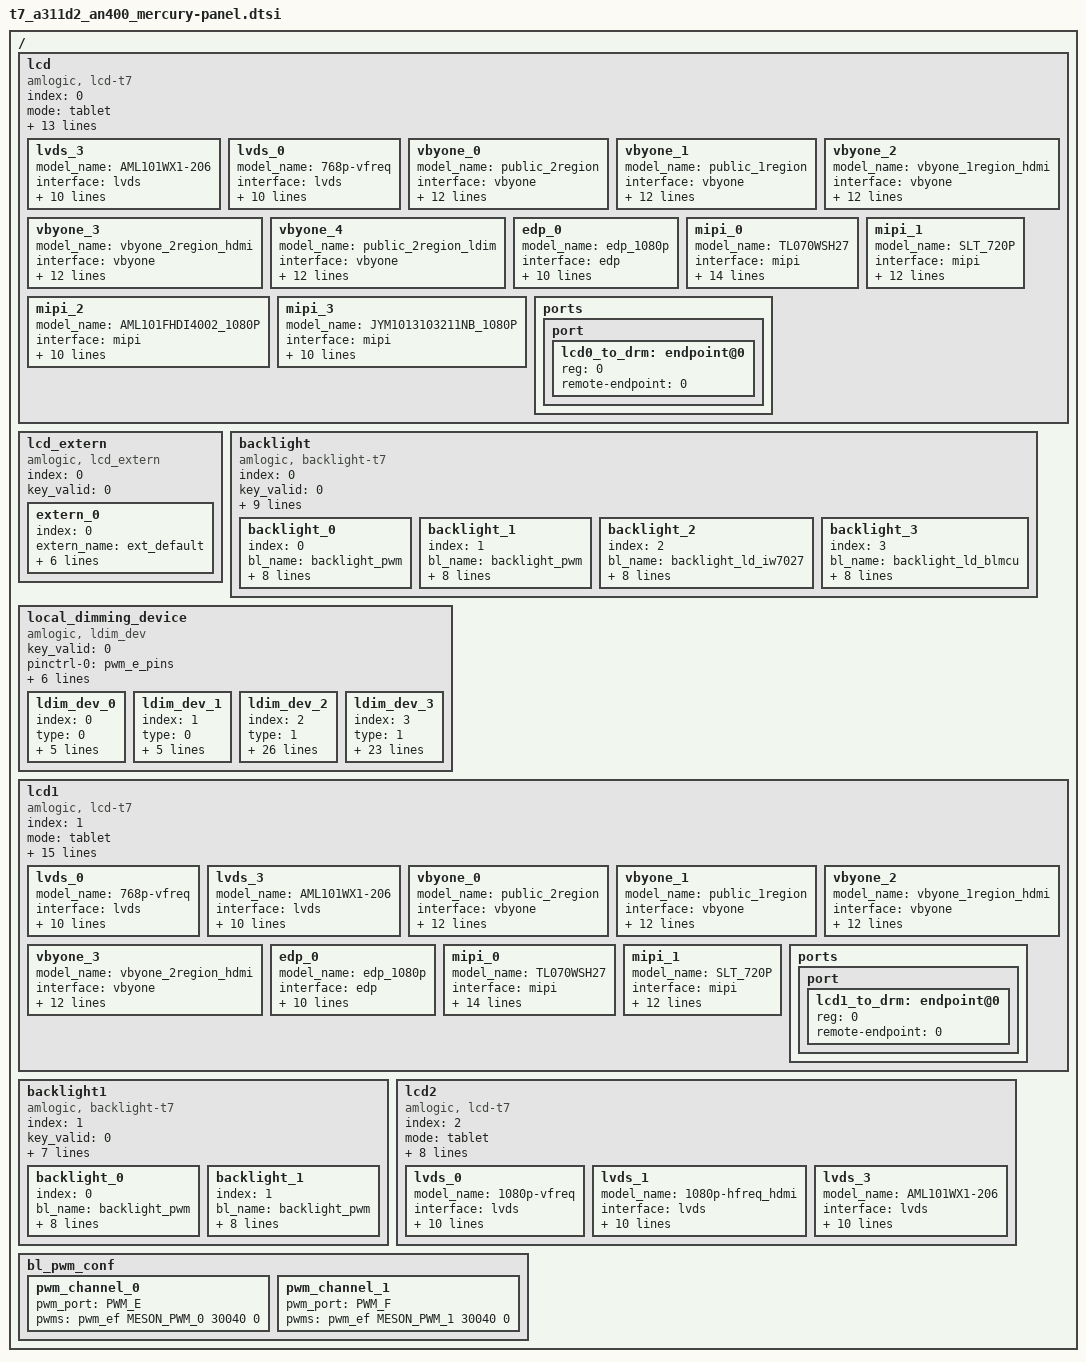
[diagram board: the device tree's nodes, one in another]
// SPDX-License-Identifier: (GPL-2.0+ OR MIT)
/*
 * Copyright (c) 2019 Amlogic, Inc. All rights reserved.
 */

/ {
	lcd:lcd {
		compatible = "amlogic, lcd-t7";
		status = "okay";
		index = <0>;
		mode = "tablet";
		fr_auto_policy = <0>; /* 0=disable, 1=60/50hz, 2=60/50/48hz */
		key_valid = <0>;
		clocks = <&clkc CLKID_MIPI_DSI_A
			&clkc CLKID_DSI0_PHY_GATE
			&clkc CLKID_DSI_A_MEAS_GATE>;
		clock-names = "dsi_host_gate",
			"dsi_phy_gate",
			"dsi_meas";
		reg = <0x0 0xfe018000 0x0 0x60	   /* combo dphy */
			0x0 0xfe0b0000 0x0 0x10b0  /* edp_a host */
			0x0 0xfe074000 0x0 0x400   /* mipi_dsi_a host */
			0x0 0xfe014000 0x0 0x200   /* mipi_dsi_a phy */
			0x0 0xfe002000 0x0 0xa0	   /* reset */
			0x0 0xfe004000 0x0 0x70>;  /* periphs */
		interrupts = <0 197 1
			0 194 1
			0 82 1
			0 282 1>;
		interrupt-names = "vsync","vsync2","vsync3","vbyone";
		pinctrl-names = "vbyone","vbyone_off","edp","edp_off";
		pinctrl-0 = <&lcd_vbyone_a_pins>;
		pinctrl-1 = <&lcd_vbyone_a_off_pins>;
		pinctrl-2 = <&lcd_edp_a_pins>;
		pinctrl-3 = <&lcd_edp_a_off_pins>;
		pinctrl_version = <2>; /* for uboot */

		/* power type:(0=cpu_gpio, 2=signal, 3=extern, 0xff=ending) */
		/* power index:(gpios_index, or extern_index, 0xff=invalid) */
		/* power value:(0=output low, 1=output high, 2=input) */
		/* power delay:(unit in ms) */
		/*lcd_cpu-gpios = <&gpio GPIOY_0 GPIO_ACTIVE_HIGH */
		/*	&gpio GPIOY_4 GPIO_ACTIVE_HIGH */
		/*	&gpio GPIOY_6 GPIO_ACTIVE_HIGH>; */
		/*lcd_cpu_gpio_names = "GPIOY_0","GPIOY_4","GPIOY_6";*/

		lvds_3{
			model_name = "AML101WX1-206";
			interface = "lvds"; /*lcd_interface(lvds, vbyone)*/
			basic_setting = <
				1280 800 /*h_active, v_active*/
				1310 813 /*h_period, v_period*/
				8	   /*lcd_bits*/
				217 136>; /*screen_widht, screen_height*/
			range_setting = <
				1280 1280 /*h_period_min, max */
				800 800	 /*v_period_min, max */
				400000000 800000000>; /*pclk_min, max*/
			lcd_timing = <
				2 14 0	 /*hs_width, hs_bp, hs_pol*/
				1 6 0>; /*vs_width, vs_bp, vs_pol*/
			clk_attr = <
				0 /*fr_adj_type
				   *(0=clk, 1=htotal, 2=vtotal, 3=auto_range,
				   * 4=hdmi_mode)
				   */
				15 /*clk_ss_level*/
				1 /*clk_auto_generate*/
				60>; /*pixel_clk(unit in Hz)*/
			lvds_attr = <
				1  /*lvds_repack*/
				0  /*dual_port*/
				0  /*pn_swap*/
				1  /*port_swap*/
				0>; /*lane_reverse*/
			phy_attr=<0x3 0>; /*vswing_level, preem_level*/

			/* power step: type, index, value, delay(ms) */
			power_on_step = <
				0 0 1 50  /*panel power on*/
				2 0 0 0	  /*signal enable*/
				0xff 0 0 0>; /*ending*/
			power_off_step = <
				2 0 0 10  /*signal disable*/
				0 0 0 100  /*panel power off*/
				0xff 0 0 0>; /*ending*/
			backlight_index = <0xff>;
		};
		lvds_0{
			model_name = "768p-vfreq";
			interface = "lvds"; /*lcd_interface(lvds, vbyone)*/
			basic_setting = <
				1366 768 /*h_active, v_active*/
				1560 806 /*h_period, v_period*/
				8	   /*lcd_bits*/
				16 9>; /*screen_widht, screen_height*/
			range_setting = <
				1460 2000 /*h_period_min, max */
				784 1015  /*v_period_min, max */
				50000000 85000000>; /*pclk_min, max*/
			lcd_timing = <
				56 64 0	  /*hs_width, hs_bp, hs_pol*/
				3  28 0>; /*vs_width, vs_bp, vs_pol*/
			clk_attr = <
				2 /*fr_adj_type
				   *(0=clk, 1=htotal, 2=vtotal, 3=auto_range,
				   * 4=hdmi_mode)
				   */
				15 /*clk_ss_level*/
				1 /*clk_auto_generate*/
				0>; /*pixel_clk(unit in Hz)*/
			lvds_attr = <
				1  /*lvds_repack*/
				0  /*dual_port*/
				0  /*pn_swap*/
				0  /*port_swap*/
				0>; /*lane_reverse*/
			phy_attr=<0x3 0>; /*vswing_level, preem_level*/

			/* power step: type, index, value, delay(ms) */
			power_on_step = <
				0 0 1 50  /*panel power on*/
				2 0 0 0	  /*signal enable*/
				0xff 0 0 0>; /*ending*/
			power_off_step = <
				2 0 0 10  /*signal disable*/
				0 0 0 100 /*panel power off*/
				0xff 0 0 0>; /*ending*/
			backlight_index = <0xff>;
		};
		vbyone_0{
			model_name = "public_2region";
			interface = "vbyone"; /*lcd_interface(lvds, vbyone)*/
			basic_setting = <
				3840 2160 /*h_active, v_active*/
				4400 2250 /*h_period, v_period*/
				10	   /*lcd_bits */
				16 9>; /*screen_widht, screen_height*/
			range_setting = <
				4240 4800 /*h_period_min, max*/
				2200 2760 /*v_period_min, max*/
				480000000 624000000>; /*pclk_min, max*/
			lcd_timing = <
				33 477 0  /*hs_width, hs_bp, hs_pol*/
				6  65 0>; /*vs_width, vs_bp, vs_pol*/
			clk_attr = <
				2 /*fr_adj_type
				   *(0=clk, 1=htotal, 2=vtotal, 3=auto_range,
				   * 4=hdmi_mode)
				   */
				0 /*clk_ss_level*/
				1 /*clk_auto_generate*/
				0>; /*pixel_clk(unit in Hz)*/
			vbyone_attr = <
				8 /*lane_count*/
				2 /*region_num*/
				4 /*byte_mode*/
				4>; /*color_fmt*/
			vbyone_intr_enable = <
				1 /*vbyone_intr_enable */
				3>; /*vbyone_vsync_intr_enable*/
			phy_attr=<0x7 1>; /* vswing_level, preem_level */
			hw_filter=<0 0>;  /* filter_time, filter_cnt*/

			/* power step: type, index, value, delay(ms) */
			power_on_step = <
				0 0 1 200  /*panel power on*/
				2 0 0 10  /*signal enable*/
				0xff 0 0 0>; /*ending*/
			power_off_step = <
				2 0 0 10 /*signal disable*/
				0 0 0 500 /*panel power off*/
				0xff 0 0 0>; /*ending*/
			backlight_index = <0>;
		};
		vbyone_1{
			model_name = "public_1region";
			interface = "vbyone"; /*lcd_interface(lvds, vbyone)*/
			basic_setting = <
				3840 2160 /*h_active, v_active*/
				4400 2250 /*h_period, v_period*/
				10	   /*lcd_bits*/
				16 9>; /*screen_widht, screen_height*/
			range_setting = <
				4240 4800 /*h_period_min, max*/
				2200 2790 /*v_period_min, max*/
				552000000 632000000>; /*pclk_min,max*/
			lcd_timing = <
				33 477 0   /*hs_width, hs_bp, hs_pol*/
				6  65  0>; /*vs_width, vs_bp, vs_pol*/
			clk_attr = <
				2 /*fr_adj_type
				   *(0=clk, 1=htotal, 2=vtotal, 3=auto_range,
				   * 4=hdmi_mode)
				   */
				0 /*clk_ss_level*/
				1 /*clk_auto_generate*/
				0>; /*pixel_clk(unit in Hz)*/
			vbyone_attr = <
				8 /*lane_count*/
				1 /*region_num*/
				4 /*byte_mode*/
				4>; /*color_fmt*/
			vbyone_intr_enable = <
				1	/*vbyone_intr_enable*/
				3>; /*vbyone_vsync_intr_enable*/
			phy_attr=<0x7 1>; /* vswing_level, preem_level */
			hw_filter=<0 0>;  /* filter_time, filter_cnt*/

			/* power step: type, index, value, delay(ms) */
			power_on_step = <
				0 0 1 200  /*panel power on*/
				2 0 0 10 /*signal enable*/
				0xff 0 0 0>; /*ending*/
			power_off_step = <
				2 0 0 10  /*signal disable*/
				0 0 0 500 /*panel power off*/
				0xff 0 0 0>; /*ending*/
			backlight_index = <0>;
		};
		vbyone_2{
			model_name = "vbyone_1region_hdmi";
			interface = "vbyone"; /*lcd_interface(lvds, vbyone)*/
			basic_setting = <
				3840 2160 /*h_active, v_active*/
				4400 2250 /*h_period, v_period*/
				10	   /*lcd_bits */
				16 9>; /*screen_widht, screen_height*/
			range_setting = <
				4240 4800 /*h_period_min, max*/
				2200 2760 /*v_period_min, max*/
				480000000 624000000>; /*pclk_min, max*/
			lcd_timing = <
				33 477 0  /*hs_width, hs_bp, hs_pol*/
				6  65 0>; /*vs_width, vs_bp, vs_pol*/
			clk_attr = <
				4 /*fr_adj_type
				   *(0=clk, 1=htotal, 2=vtotal, 3=auto_range,
				   * 4=hdmi_mode)
				   */
				0 /*clk_ss_level*/
				1 /*clk_auto_generate*/
				0>; /*pixel_clk(unit in Hz)*/
			vbyone_attr = <
				8 /*lane_count*/
				1 /*region_num*/
				4 /*byte_mode*/
				4>; /*color_fmt*/
			vbyone_intr_enable = <
				1 /*vbyone_intr_enable */
				3>; /*vbyone_vsync_intr_enable*/
			phy_attr=<0x7 1>; /* vswing_level, preem_level */
			hw_filter=<0 0>;  /* filter_time, filter_cnt*/

			/* power step: type, index, value, delay(ms) */
			power_on_step = <
				0 0 1 20  /*panel power on*/
				2 0 0 0	 /*signal enable*/
				0xff 0 0 0>; /*ending*/
			power_off_step = <
				2 0 0 20 /*signal disable*/
				0 0 0 100 /*panel power off*/
				0xff 0 0 0>; /*ending*/
			backlight_index = <0xff>;
		};
		vbyone_3{
			model_name = "vbyone_2region_hdmi";
			interface = "vbyone"; /*lcd_interface(lvds, vbyone)*/
			basic_setting = <
				3840 2160 /*h_active, v_active*/
				4400 2250 /*h_period, v_period*/
				10	   /*lcd_bits */
				16 9>; /*screen_widht, screen_height*/
			range_setting = <
				4240 4800 /*h_period_min, max*/
				2200 2760 /*v_period_min, max*/
				480000000 624000000>; /*pclk_min, max*/
			lcd_timing = <
				33 477 0  /*hs_width, hs_bp, hs_pol*/
				6  65 0>; /*vs_width, vs_bp, vs_pol*/
			clk_attr = <
				4 /*fr_adj_type
				   *(0=clk, 1=htotal, 2=vtotal, 3=auto_range,
				   * 4=hdmi_mode)
				   */
				0 /*clk_ss_level*/
				1 /*clk_auto_generate*/
				0>; /*pixel_clk(unit in Hz)*/
			vbyone_attr = <
				8 /*lane_count*/
				2 /*region_num*/
				4 /*byte_mode*/
				4>; /*color_fmt*/
			vbyone_intr_enable = <
				1 /*vbyone_intr_enable */
				3>; /*vbyone_vsync_intr_enable*/
			phy_attr=<0x7 1>; /* vswing_level, preem_level */
			hw_filter=<0 0>;  /* filter_time, filter_cnt*/

			/* power step: type, index, value, delay(ms) */
			power_on_step = <
				0 0 1 20  /*panel power on*/
				2 0 0 0	 /*signal enable*/
				0xff 0 0 0>; /*ending*/
			power_off_step = <
				2 0 0 20 /*signal disable*/
				0 0 0 100 /*panel power off*/
				0xff 0 0 0>; /*ending*/
			backlight_index = <0xff>;
		};
		vbyone_4{/*for localdimming*/
			model_name = "public_2region_ldim";
			interface = "vbyone"; /*lcd_interface(lvds, vbyone)*/
			basic_setting = <
				3840 2160 /*h_active, v_active*/
				4400 2250 /*h_period, v_period*/
				10	   /*lcd_bits */
				16 9>; /*screen_widht, screen_height*/
			range_setting = <
				4240 4800 /*h_period_min, max*/
				2200 2760 /*v_period_min, max*/
				480000000 624000000>; /*pclk_min, max*/
			lcd_timing = <
				33 477 0  /*hs_width, hs_bp, hs_pol*/
				6  65 0>; /*vs_width, vs_bp, vs_pol*/
			clk_attr = <
				2 /*fr_adj_type
				   *(0=clk, 1=htotal, 2=vtotal, 3=auto_range,
				   * 4=hdmi_mode)
				   */
				0 /*clk_ss_level*/
				1 /*clk_auto_generate*/
				0>; /*pixel_clk(unit in Hz)*/
			vbyone_attr = <
				8 /*lane_count*/
				2 /*region_num*/
				4 /*byte_mode*/
				4>; /*color_fmt*/
			vbyone_intr_enable = <
				1 /*vbyone_intr_enable */
				3>; /*vbyone_vsync_intr_enable*/
			phy_attr=<0x7 1>; /* vswing_level, preem_level */
			hw_filter=<0 0>;  /* filter_time, filter_cnt*/

			/* power step: type, index, value, delay(ms) */
			power_on_step = <
				0 2 1 200  /*panel power on*/
				2 0 0 10  /*signal enable*/
				0xff 0 0 0>; /*ending*/
			power_off_step = <
				2 0 0 10 /*signal disable*/
				0 2 0 500 /*panel power off*/
				0xff 0 0 0>; /*ending*/
			backlight_index = <3>;
		};

		edp_0{
			model_name = "edp_1080p";
			interface = "edp"; /*lcd_interface(lvds, vbyone)*/
			basic_setting = <
				1920 1080 /*h_active, v_active*/
				2200 1125 /*h_period, v_period*/
				8	   /*lcd_bits*/
				16 9>; /*screen_widht, screen_height*/
			range_setting = <
				2080 2720 /*h_period min, max*/
				1100 1380 /*v_period min, max*/
				133940000 156000000>; /*pclk_min, max*/
			lcd_timing = <
				44 148 0   /*hs_width, hs_bp, hs_pol*/
				5  30  0>; /*vs_width, vs_bp, vs_pol*/
			clk_attr = <
				0 /*fr_adj_type
				   *(0=clk, 1=htotal, 2=vtotal, 3=auto_range,
				   * 4=hdmi_mode)
				   */
				0 /*clk_ss_level */
				1 /*clk_auto_generate*/
				0>; /*pixel_clk(unit in Hz)*/
			edp_attr = <
				2 /*max_lane_count: 1,2,4*/
				1 /*max_link_rate: 0=1.62G, 1=2.7G*/
				0 /*training_mode*/
				0 /*edid_en, auto timing by edid*/
				0 /*reserved */
				0 /*reserved */
				0 /*reserved */
				0 /*reserved */
				0>; /*reserved*/
			phy_attr=<0x5 1>; /*vswing_level, preem_level*/

			/* power step: type, index, value, delay(ms) */
			power_on_step = <
				0 0 1 50  /*panel power on*/
				2 0 0 0	  /*signal enable*/
				0xff 0 0 0>; /*ending*/
			power_off_step = <
				2 0 0 10  /*signal disable*/
				0 0 0 200  /*panel power on*/
				0xff 0 0 0>; /*ending*/
			backlight_index = <0x0>;
		};
		mipi_0{
			model_name = "TL070WSH27";
			interface = "mipi";
			basic_setting = <1024 600 /*h_active, v_active*/
				1250 630 /*h_period, v_period*/
				8 /*lcd_bits*/
				154 86>; /*screen_widht, screen_height*/
			lcd_timing = <80 100 0 /*hs_width, hs_bp, hs_pol*/
				5 20 0>; /*vs_width, vs_bp, vs_pol*/
			clk_attr = <0 /*fr_adj_type(0=clk, 1=htotal, 2=vtotal)*/
				0 /*clk_ss_level */
				1 /*clk_auto_generate*/
				47250000>; /*pixel_clk(unit in Hz)*/
			mipi_attr = <4 /*lane_num*/
				300 /*bit_rate_max(MHz)*/
				0 /*factor(*100, default 0 for auto)*/
				1 /*operation_mode_init(0=video, 1=command)*/
				0 /*operation_mode_display(0=video, 1=command)*/
				2 /*
				   *video_mode_type
				   *(0=sync_pulse,1=sync_event,2=burst)
				   */
				1 /*clk_always_hs(0=disable,1=enable)*/
				0>; /*phy_switch(0=auto,1=standard,2=slow)*/

			/* dsi_init: data_type, num, data... */
			dsi_init_on = <0x05 1 0x11
					0xfd 1 20	  /*delay(ms)*/
					0x05 1 0x29
					0xfd 1 20	  /*delay(ms)*/
					0xff 0>; /*ending*/
			dsi_init_off = <0x05 1 0x28
					0xfd 1 10	  /*delay(ms)*/
					0x05 1 0x10
					0xfd 1 10	  /*delay(ms)*/
					0xff 0>; /*ending*/
			extern_init = <0xff>; /*0xff for invalid*/

			/* power step: type, index, value, delay(ms) */
			power_on_step = <
				0 0 1 100
				0 1 0 10
				0 1 1 20
				2 0 0 0
				0xff 0 0 0>; /*ending*/
			power_off_step = <
				2 0 0 50
				0 1 0 10
				0 0 0 100
				0xff 0 0 0>; /*ending*/
			backlight_index = <0x1>;
		};
		mipi_1{
			model_name = "SLT_720P";
			interface = "mipi";
			basic_setting = <1280 720 /*h_active, v_active*/
				1590 750 /*h_period, v_period*/
				8 /*lcd_bits*/
				16 9>; /*screen_widht, screen_height*/
			lcd_timing = <40 60 0 /*hs_width,hs_bp,hs_pol*/
				5 20 0>; /*vs_width,vs_bp,vs_pol*/
			clk_attr = <0 /*fr_adj_type(0=clock,1=htotal,2=vtotal)*/
				0 /*clk_ss_level*/
				1 /*clk_auto_generate*/
				74250000>; /*pixel_clk(unit in Hz)*/
			mipi_attr = <4 /*lane_num*/
				550 /*bit_rate_max(MHz)*/
				0 /*factor(*100, default 0 for auto)*/
				1 /*operation_mode_init(0=video, 1=command)*/
				0 /*operation_mode_display(0=video, 1=command)*/
				0 /*
				   *video_mode_type
				   *(0=sync_pulse,1=sync_event,2=burst)
				   */
				1 /*clk_always_hs(0=disable,1=enable)*/
				0>; /*phy_switch(0=auto,1=standard,2=slow)*/
				/* dsi_init: data_type, num, data... */
			dsi_init_on = <
				0x05 1 0x11
				0xff 200
				0x05 1 0x29
				0xff 20
				0xff 0xff>; /* ending flag */
			dsi_init_off = <
				0x05 1 0x28
				0xff 10
				0x05 1 0x10
				0xff 10
				0xff 0xff>; /* ending flag */
				/* extern_init: 0xff for invalid */
			extern_init = <0xff>;
				/* power step: type,index,value,delay(ms) */
			power_on_step = <
					3 7 0 100
					2 0 0 0
					0xff 0 0 0>;
			power_off_step = <
					2 0 0 0
					0xff 0 0 0>;
			backlight_index = <0xff>;
		};
		mipi_2{
			model_name = "AML101FHDI4002_1080P";
			interface = "mipi";
			basic_setting = <800 1280/*h_active, v_active*/
					950 1324 /*h_period, v_period*/
					8 /*lcd_bits*/
					136 217>; /*screen_widht, screen_height*/
			lcd_timing = <30 60 0 /*hs_width,hs_bp,hs_pol*/
					8 16 0>; /*vs_width,vs_bp,vs_pol*/
			clk_attr = <0 /*fr_adj_type(0=clock,1=htotal,2=vtotal)*/
					0 /*clk_ss_level*/
					1 /*clk_auto_generate*/
					67800000>; /*pixel_clk(unit in Hz)*/
			mipi_attr = <4 /*lane_num*/
					480 /*bit_rate_max(MHz)*/
					0 /*factor(*100, default 0 for auto)*/
					1 /*operation_mode_init(0=video, 1=command)*/
					0 /*operation_mode_display(0=video, 1=command)*/
					2 /*
					   *video_mode_type
					   *(0=sync_pulse,1=sync_event,2=burst)
					   */
					1 /*clk_always_hs(0=disable,1=enable)*/
					0>; /*phy_switch(0=auto,1=standard,2=slow)*/
			/* dsi_init: data_type, num, data... */
			dsi_init_on = <0xFF 0>;	/*ending*/
			init_off = <0xff 0>;	/*ending*/
			/* extern_init: 0xff for invalid */
			extern_init = <0>;
					/* power step: type,index,value,delay(ms) */
			power_on_step = <
				2 0 0 100
				0xff 0 0 0>;
			power_off_step = <
				2 0 0 0
				0xff 0 0 0>;
			backlight_index = <0xff>;
		};
		mipi_3{
			model_name = "JYM1013103211NB_1080P";
			interface = "mipi";
			basic_setting = <1200 1920/*h_active, v_active*/
				   1341 2001 /*h_period, v_period*/
				   8 /*lcd_bits*/
				   135 216>; /*screen_widht, screen_height*/
			lcd_timing = <1 60 0 /*hs_width,hs_bp,hs_pol*/
				   1 25 0>; /*vs_width,vs_bp,vs_pol*/
			clk_attr = <0 /*fr_adj_type(0=clock,1=htotal,2=vtotal)*/
				   0 /*clk_ss_level*/
				   1 /*clk_auto_generate*/
				   161000460>; /*pixel_clk(unit in Hz)*/
			mipi_attr = <4 /*lane_num*/
				   1000 /*bit_rate_max(MHz)*/
				   0 /*factor(*100, default 0 for auto)*/
				   1 /*operation_mode_init(0=video, 1=command)*/
				   0 /*operation_mode_display(0=video, 1=command)*/
				   2 /*
				      *video_mode_type
				      *(0=sync_pulse,1=sync_event,2=burst)
				      */
				   1 /*clk_always_hs(0=disable,1=enable)*/
				   0>; /*phy_switch(0=auto,1=standard,2=slow)*/
			/* dsi_init: data_type, num, data... */
			dsi_init_on = <0xff 0xff>; /* ending flag */
			dsi_init_off = <0xff 0xff>; /* ending flag */
			/* extern_init: 0xff for invalid */
			extern_init = <0xff>;
			/* power step: type,index,value,delay(ms) */
			power_on_step = <
				2 0 0 100
				0xff 0 0 0>;
			power_off_step = <
				2 0 0 0
				0xff 0 0 0>;
			backlight_index = <0xff>;
		};

		ports {
			port {
				#address-cells = <1>;
				#size-cells = <0>;
				lcd0_to_drm: endpoint@0 {
					reg = <0>;
					remote-endpoint = <0>;
				};
			};
		};
	};

	lcd_extern{
		compatible = "amlogic, lcd_extern";
		status = "okay";
		index = <0>;
		key_valid = <0>;
		//i2c_bus = "i2c_bus_2";

		extern_0{
			index = <0>;
			extern_name = "ext_default";
			status = "okay";
			type = <2>; /*0=i2c, 1=spi, 2=mipi*/
			cmd_size = <0xff>; /*dynamic cmd_size*/

			/* init on/off:
			 *  fixed cmd_size: (type, value...);
			 *                  cmd_size include all data.
			 *  dynamic cmd_size: (type, cmd_size, value...);
			 *                    cmd_size include value.
			 */
			/* type: 0x00=cmd with delay(bit[3:0]=1 for address2),
			 *       0xc0=cmd(bit[3:0]=1 for address2),
			 *       0xf0=gpio,
			 *       0xfd=delay,
			 *       0xff=ending
			 */
			/* value: i2c or spi cmd, or gpio index & level */
			/* delay: unit ms */
			init_on = <
				0x39 4 0xFF 0x98 0x81 0x03
				0x23 2 0x01 0x00
				0x23 2 0x02 0x00
				0x23 2 0x03 0x53
				0x23 2 0x04 0x00
				0x23 2 0x05 0x00
				0x23 2 0x06 0x08
				0x23 2 0x07 0x00
				0x23 2 0x08 0x00
				0x23 2 0x09 0x00
				0x23 2 0x0a 0x00
				0x23 2 0x0b 0x00
				0x23 2 0x0c 0x00
				0x23 2 0x0d 0x00
				0x23 2 0x0e 0x00
				0x23 2 0x0f 0x26
				0x23 2 0x10 0x26
				0x23 2 0x11 0x00
				0x23 2 0x12 0x00
				0x23 2 0x13 0x00
				0x23 2 0x14 0x00
				0x23 2 0x15 0x00
				0x23 2 0x16 0x00
				0x23 2 0x17 0x00
				0x23 2 0x18 0x00
				0x23 2 0x19 0x00
				0x23 2 0x1a 0x00
				0x23 2 0x1b 0x00
				0x23 2 0x1c 0x00
				0x23 2 0x1d 0x00
				0x23 2 0x1e 0x40
				0x23 2 0x1f 0xC0
				0x23 2 0x20 0x06
				0x23 2 0x21 0x01
				0x23 2 0x22 0x07
				0x23 2 0x23 0x00
				0x23 2 0x24 0x8A
				0x23 2 0x25 0x8A
				0x23 2 0x26 0x00
				0x23 2 0x27 0x00
				0x23 2 0x28 0x33
				0x23 2 0x29 0x33
				0x23 2 0x2a 0x00
				0x23 2 0x2b 0x00
				0x23 2 0x2c 0x08
				0x23 2 0x2d 0x08
				0x23 2 0x2e 0x0B
				0x23 2 0x2f 0x0B
				0x23 2 0x30 0x00
				0x23 2 0x31 0x00
				0x23 2 0x32 0x42
				0x23 2 0x33 0x00
				0x23 2 0x34 0x00
				0x23 2 0x35 0x0A
				0x23 2 0x36 0x00
				0x23 2 0x37 0x08
				0x23 2 0x38 0x3C
				0x23 2 0x39 0x00
				0x23 2 0x3a 0x00
				0x23 2 0x3b 0x00
				0x23 2 0x3c 0x00
				0x23 2 0x3d 0x00
				0x23 2 0x3e 0x00
				0x23 2 0x3f 0x00
				0x23 2 0x40 0x00
				0x23 2 0x41 0x00
				0x23 2 0x42 0x00
				0x23 2 0x43 0x08
				0x23 2 0x44 0x00
				0x23 2 0x50 0x01
				0x23 2 0x51 0x23
				0x23 2 0x52 0x45
				0x23 2 0x53 0x67
				0x23 2 0x54 0x89
				0x23 2 0x55 0xab
				0x23 2 0x56 0x01
				0x23 2 0x57 0x23
				0x23 2 0x58 0x45
				0x23 2 0x59 0x67
				0x23 2 0x5a 0x89
				0x23 2 0x5b 0xab
				0x23 2 0x5c 0xcd
				0x23 2 0x5d 0xef
				0x23 2 0x5e 0x00
				0x23 2 0x5f 0x01
				0x23 2 0x60 0x01
				0x23 2 0x61 0x06
				0x23 2 0x62 0x06
				0x23 2 0x63 0x06
				0x23 2 0x64 0x06
				0x23 2 0x65 0x00
				0x23 2 0x66 0x00
				0x23 2 0x67 0x17
				0x23 2 0x68 0x02
				0x23 2 0x69 0x16
				0x23 2 0x6a 0x16
				0x23 2 0x6b 0x02
				0x23 2 0x6c 0x0D
				0x23 2 0x6d 0x0D
				0x23 2 0x6e 0x0C
				0x23 2 0x6f 0x0C
				0x23 2 0x70 0x0F
				0x23 2 0x71 0x0F
				0x23 2 0x72 0x0E
				0x23 2 0x73 0x0E
				0x23 2 0x74 0x02
				0x23 2 0x75 0x01
				0x23 2 0x76 0x01
				0x23 2 0x77 0x06
				0x23 2 0x78 0x06
				0x23 2 0x79 0x06
				0x23 2 0x7a 0x06
				0x23 2 0x7b 0x00
				0x23 2 0x7c 0x00
				0x23 2 0x7d 0x17
				0x23 2 0x7e 0x02
				0x23 2 0x7f 0x16
				0x23 2 0x80 0x16
				0x23 2 0x81 0x02
				0x23 2 0x82 0x0D
				0x23 2 0x83 0x0D
				0x23 2 0x84 0x0C
				0x23 2 0x85 0x0C
				0x23 2 0x86 0x0F
				0x23 2 0x87 0x0F
				0x23 2 0x88 0x0E
				0x23 2 0x89 0x0E
				0x23 2 0x8A 0x02
				0x39 4 0xFF 0x98 0x81 0x04
				0x23 2 0x6E 0x2B
				0x23 2 0x6F 0x35
				0x23 2 0x3A 0xA4
				0x23 2 0x8D 0x1A
				0x23 2 0x87 0xBA
				0x23 2 0xB2 0xD1
				0x23 2 0x88 0x0B
				0x23 2 0x38 0x01
				0x23 2 0x39 0x00
				0x23 2 0xB5 0x07
				0x23 2 0x31 0x75
				0x23 2 0x3B 0x98
				0x39 4 0xFF 0x98 0x81 0x01
				//CMD_Page 1
				0x23 2 0x22 0x0A
				0x23 2 0x31 0x00
				0x23 2 0x53 0x40
				0x23 2 0x55 0x40
				0x23 2 0x50 0x95
				0x23 2 0x51 0x90
				0x23 2 0x60 0x22
				0x23 2 0x62 0x20
				0x23 2 0xA0 0x00
				0x23 2 0xA1 0x17
				0x23 2 0xA2 0x26
				0x23 2 0xA3 0x13
				0x23 2 0xA4 0x17
				0x23 2 0xA5 0x2A
				0x23 2 0xA6 0x1E
				0x23 2 0xA7 0x20
				0x23 2 0xA8 0x8F
				0x23 2 0xA9 0x1D
				0x23 2 0xAA 0x2A
				0x23 2 0xAB 0x7B
				0x23 2 0xAC 0x1B
				0x23 2 0xAD 0x1A
				0x23 2 0xAE 0x4D
				0x23 2 0xAF 0x23
				0x23 2 0xB0 0x29
				0x23 2 0xB1 0x4C
				0x23 2 0xB2 0x59
				0x23 2 0xB3 0x23
				0x23 2 0xC0 0x00
				0x23 2 0xC1 0x16
				0x23 2 0xC2 0x25
				0x23 2 0xC3 0x13
				0x23 2 0xC4 0x16
				0x23 2 0xC5 0x2A
				0x23 2 0xC6 0x1E
				0x23 2 0xC7 0x20
				0x23 2 0xC8 0x8E
				0x23 2 0xC9 0x1E
				0x23 2 0xCA 0x2A
				0x23 2 0xCB 0x7B
				0x23 2 0xCC 0x1A
				0x23 2 0xCD 0x19
				0x23 2 0xCE 0x4E
				0x23 2 0xCF 0x23
				0x23 2 0xD0 0x29
				0x23 2 0xD1 0x4C
				0x23 2 0xD2 0x59
				0x23 2 0xD3 0x23
				0x39 4 0xFF 0x98 0x81 0x00
				0x23 2 0x11 0x00
				0xfd 1 120
				0x23 2 0x29 0x00
				0x23 2 0x35 0x00
				//0xfd 1 20	  /* delay(ms) */
				0xFF 0>; /*ending*/
			init_off = <0x05 1 0x28 /* display off */
				0xfd 1 10	/* delay 10ms */
				0x05 1 0x10 /* sleep in */
				0xfd 1 150	/* delay 150ms */
				0xff 0>; /*ending*/
		};
	};

	backlight{
		compatible = "amlogic, backlight-t7";
		status = "okay";
		index = <0>;
		key_valid = <0>;
		pinctrl-names = "pwm_on","pwm_off";
		pinctrl-0 = <&pwm_e_pins>; /* GPIOY_1*/
		pinctrl-1 = <&bl_pwm_off_pins>; /* GPIOY_1*/
		pinctrl_version = <2>; /* for uboot */
		interrupts-extended = <&gic 0 197 1>,
			<&gic 0 194 1>,
			<&gic 0 82 1>,
			<&gpio_intc 143 1>;
		interrupt-names = "vsync","vsync2","vsync3","ldim_pwm_vs";
		bl_pwm_config = <&bl_pwm_conf>;
		memory-region = <&ldc_mem_reserved>;

		/* pwm port: PWM_A, PWM_B, PWM_C, PWM_D, PWM_E, PWM_F, PWM_VS*/
		/* power index:(point gpios_index, 0xff=invalid) */
		/* power value:(0=output low, 1=output high, 2=input) */
		/* power delay:(unit in ms) */
		bl-gpios = <&gpio GPIOY_5 GPIO_ACTIVE_HIGH
			&gpio GPIOY_1 GPIO_ACTIVE_HIGH>;
		bl_gpio_names = "GPIOY_5","GPIOY_1";

		backlight_0{
			index = <0>;
			bl_name = "backlight_pwm";
			bl_level_default_uboot_kernel = <255 255>;
			bl_level_attr = <255 10 /*max, min*/
				128 128>; /*mid, mid_mapping*/
			bl_ctrl_method = <1>; /*1=pwm,2=pwm_combo,3=ldim*/
			bl_power_attr = <0 /*en_gpio_index*/
				1 0 /*on_value, off_value*/
				200 200>; /*on_delay(ms), off_delay(ms)*/
			bl_pwm_port = "PWM_E";
			bl_pwm_attr = <1 /*pwm_method(0=negative, 1=positvie)*/
				180 /*pwm_freq(pwm:Hz, pwm_vs:multiple of vs)*/
				100 25>; /*duty_max(%), duty_min(%)*/
			bl_pwm_power = <1 0 /*pwm_gpio_index, pwm_gpio_off*/
				10 10>; /*pwm_on_delay(ms), pwm_off_delay(ms)*/
			en_sequence_reverse = <0>; /* 1 for reverse */
		};

		backlight_1{
			index = <1>;
			bl_name = "backlight_pwm";
			bl_level_default_uboot_kernel = <255 255>;
			bl_level_attr = <255 10 /*max, min*/
				128 128>; /*mid, mid_mapping*/
			bl_ctrl_method = <1>; /*1=pwm,2=pwm_combo*/
			bl_power_attr = <0 /*en_gpio_index*/
				1 0 /*on_value, off_value*/
				200 200>; /*on_delay(ms), off_delay(ms)*/
			bl_pwm_port = "PWM_E";
			bl_pwm_attr = <0 /*pwm_method(0=negative, 1=positvie)*/
				180 /*pwm_freq(pwm:Hz, pwm_vs:multiple of vs)*/
				100 25>; /*duty_max(%), duty_min(%)*/
			bl_pwm_power = <1 0 /*pwm_gpio_index, pwm_gpio_off*/
				10 10>; /*pwm_on_delay(ms), pwm_off_delay(ms)*/
			en_sequence_reverse = <0>; /* 1 for reverse */
		};

		backlight_2{
			index = <2>;
			bl_name = "backlight_ld_iw7027";
			bl_level_default_uboot_kernel = <100 100>;
			bl_level_attr = <255 10 /*max, min*/
				128 128>; /*mid, mid_mapping*/
			bl_ctrl_method = <3>; /*1=pwm,2=pwm_combo,3=ldim*/
			bl_power_attr = <0	/*en_gpio_index*/
				1 0 /*on_value, off_value*/
				200 200>; /* on_delay(ms), off_delay(ms)*/
			en_sequence_reverse = <0>; /* 1 for reverse */
			bl_ldim_zone_row_col = <9 5>;
			bl_ldim_mode = <2>; /* 0=LR, 1=TB, 2=DIRECT */
			ldim_dev_index = <2>;
		};

		backlight_3{
			index = <3>;
			bl_name = "backlight_ld_blmcu";
			bl_level_default_uboot_kernel = <100 100>;
			bl_level_attr = <255 10 /*max, min*/
				128 128>; /*mid, mid_mapping*/
			bl_ctrl_method = <3>; /*1=pwm,2=pwm_combo,3=ldim*/
			bl_power_attr = <0	/*en_gpio_index*/
				1 0 /*on_value, off_value*/
				200 200>; /* on_delay(ms), off_delay(ms)*/
			en_sequence_reverse = <0>; /* 1 for reverse */
			bl_ldim_zone_row_col = <10 10>;
			bl_ldim_mode = <2>; /* 0=LR, 1=TB, 2=DIRECT */
			ldim_dev_index = <3>;
		};
	};

	local_dimming_device {
		compatible = "amlogic, ldim_dev";
		status = "okay";
		key_valid = <0>;
		pinctrl-names = "ldim_pwm",
			"ldim_pwm_vs",
			"ldim_pwm_off";
		pinctrl-0 = <&pwm_e_pins>;
		pinctrl-1 = <&bl_pwm_vs_on_pins>;
		pinctrl-2 = <&bl_pwm_vs_off_pins>;
		pinctrl_version = <2>; /* for uboot */
		ldim_pwm_config = <&bl_pwm_conf>;

		/* pwm port: PWM_A, PWM_B, PWM_C, PWM_D, PWM_E, PWM_F, PWM_VS*/
		ldim_dev-gpios = <&gpio GPIOY_5 GPIO_ACTIVE_HIGH>;
		ldim_dev_gpio_names = "GPIOY_5";

		ldim_dev_0 {
			index = <0>;
			type = <0>; /*0=normal, 1=spi, 2=i2c*/
			ldim_dev_name = "ob3350";
			ldim_pwm_port = "PWM_E";
			ldim_pwm_attr = <0 /* pol */
				200 /*freq(pwm:Hz, pwm_vs:multiple of vs)*/
				50>;/*default duty(%)*/
			en_gpio_on_off = <0 /*ldim_dev-gpios index*/
				1 0>; /*on_level, off_level*/
			dim_max_min = <100 20>; /*dim_max, dim_min*/
		};
		ldim_dev_1 {
			index = <1>;
			type = <0>; /*0=normal, 1=spi, 2=i2c*/
			ldim_dev_name = "global";
			ldim_pwm_port = "PWM_E";
			ldim_pwm_attr = <1 /* pol */
				180 /*freq(pwm:Hz, pwm_vs:multiple of vs)*/
				50>;/*default duty(%)*/
			en_gpio_on_off = <0 /*ldim_dev-gpios index*/
				1 0>; /*on_level, off_level*/
			dim_max_min = <100 20>; /*dim_max, dim_min*/
		};

		ldim_dev_2 {
			index = <2>;
			type = <1>; /* 0=normal,1=spi,2=i2c */
			ldim_dev_name = "iw7027";
			ldim_pwm_port = "PWM_VS";
			ldim_pwm_attr = <1	/* pol */
				2 /*freq(pwm:Hz, pwm_vs:multiple of vs)*/
				50>;/*default duty(%)*/
			spi_bus_num = <3>;
			spi_chip_select = <0>;
			spi_max_frequency = <1000000>; /* unit: hz */
			spi_mode = <0>; /* mode: 0, 1, 2, 3 */
			spi_dma_support = <1>;
			spi_cs_delay = <10	/* hold_high_delay */
				100>; /* clk_cs_delay (unit: us) */
			en_gpio_on_off = <0 /* ldim_dev-gpios index */
				1 /* on_level */
				0>; /* off_level */
			lamp_err_gpio = <0xff>;
				/* ldim_dev-gpios index, 0xff=invalid */
			spi_write_check = <0>; /* 0=disable, 1=enable */

			dim_max_min = <0xfff 0x0>; /* dim_max, dim_min */
			chip_count = <3>;
			ldim_zone_mapping = <
				37 38 39 40 41
				32 33 34 35 36
				16 17 18 19 20
				43 44 45 46 47
				27 28 29 30 31
				21 22 23 24 25
				9  8  7	 6	5
				4  3  2	 1	0
				15 14 13 12 11>;
			ldim_bl_profile_mode = <2>; /*0=no profile*/
			ldim_bl_profile_k_bits = <
				3487 24>; /*profile_k, profile_bits*/
			ldim_bl_profile_path =
				"/odm/etc/tvconfig/panel/tcon/HV650QUB-F70_LDIM/bl_profile.bin";

			ldim_cus_param = < /* maximum = 32 x 4 bytes*/
				0
				594
				268
				30550
				1231500
				20960790
				0
				5000000
				0
				0
				>;

			cmd_size = <0xff>;
			/* init: (type, data...) */
			/*	 type: 0x00=cmd with delay,
			 *		   0xc0=cmd,
			 *		   0xfd=delay,
			 *		   0xff=ending
			 */
			/*	 data: spi data, fill 0x0 for no use */
			/*	 delay: unit ms */
			init_on = <
				0xc0 2 0x00 0x06
				0xc0 2 0x01 0x00
				0xc0 2 0x02 0x00
				0xc0 2 0x03 0x00
				0xc0 2 0x04 0x22
				0xc0 2 0x05 0x00
				0xc0 2 0x06 0x44
				0xc0 2 0x07 0x00
				0xc0 2 0x08 0x66
				0xc0 2 0x09 0x00
				0xc0 2 0x0a 0x88
				0xc0 2 0x0b 0x00
				0xc0 2 0x0c 0xaa
				0xc0 2 0x0d 0x00
				0xc0 2 0x0e 0xcc
				0xc0 2 0x0f 0x00
				0xc0 2 0x10 0xee
				0xc0 2 0x11 0x51
				0xc0 2 0x12 0x10
				0xc0 2 0x13 0x32
				0xc0 2 0x14 0x00
				0xc0 2 0x15 0x54
				0xc0 2 0x16 0x55
				0xc0 2 0x17 0x76
				0xc0 2 0x18 0x99
				0xc0 2 0x19 0xbb
				0xc0 2 0x1a 0xdd
				0xc0 2 0x1b 0x00
				0xc0 2 0x1c 0xa5
				0xc0 2 0x1d 0x25
				0xc0 2 0x1e 0x88
				0xc0 2 0x1f 0x7e
				0xc0 2 0x20 0x0a
				0xc0 2 0x21 0xef
				0xc0 2 0x22 0xff
				0xc0 2 0x23 0xfb
				0xc0 2 0x24 0xff
				0xc0 2 0x25 0x00
				0xc0 2 0x26 0x00
				0xc0 2 0x27 0x33
				0xc0 2 0x28 0x33
				0xc0 2 0x29 0x87
				0xc0 2 0x2a 0x1a
				0xc0 2 0x2b 0x7f
				0xc0 2 0x2c 0xac
				0xc0 2 0x2d 0xff
				0xc0 2 0x2e 0xe4
				0xc0 2 0x2f 0xbc
				0xc0 2 0x30 0xdd
				0xc0 2 0x31 0x82
				0xc0 2 0x32 0x85
				0xc0 2 0x33 0x16
				0xc0 2 0x34 0x98
				0xc0 2 0x35 0xbf
				0xc0 2 0x36 0x41
				0xc0 2 0x37 0x00
				0xc0 2 0x38 0xc0
				0xc0 2 0x39 0x00
				0xc0 2 0x40 0x08
				0xc0 2 0x41 0x00
				0xc0 2 0x42 0x08
				0xc0 2 0x43 0x00
				0xc0 2 0x44 0x08
				0xc0 2 0x45 0x00
				0xc0 2 0x46 0x08
				0xc0 2 0x47 0x00
				0xc0 2 0x48 0x08
				0xc0 2 0x49 0x00
				0xc0 2 0x4a 0x08
				0xc0 2 0x4b 0x00
				0xc0 2 0x4c 0x08
				0xc0 2 0x4d 0x00
				0xc0 2 0x4e 0x08
				0xc0 2 0x4f 0x00
				0xc0 2 0x50 0x08
				0xc0 2 0x51 0x00
				0xc0 2 0x52 0x08
				0xc0 2 0x53 0x00
				0xc0 2 0x54 0x08
				0xc0 2 0x55 0x00
				0xc0 2 0x56 0x08
				0xc0 2 0x57 0x00
				0xc0 2 0x58 0x08
				0xc0 2 0x59 0x00
				0xc0 2 0x5a 0x08
				0xc0 2 0x5b 0x00
				0xc0 2 0x5c 0x08
				0xc0 2 0x5d 0x00
				0xc0 2 0x5e 0x08
				0xc0 2 0x5f 0x00
				0xff 0>;
			init_off = <0xff 0>;
		};

		ldim_dev_3 {
			index = <3>;
			type = <1>; /* 0=normal,1=spi,2=i2c */
			ldim_dev_name = "blmcu";
			ldim_pwm_port = "PWM_VS";
			ldim_pwm_attr = <1	/* pol */
				1 /*freq(pwm:Hz, pwm_vs:multiple of vs)*/
				2>;/*default duty(%)*/
			spi_bus_num = <3>;
			spi_chip_select = <0>;
			spi_max_frequency = <3000000>; /* unit: hz */
			spi_mode = <2>; /* mode: 0, 1, 2, 3 */
			spi_dma_support = <1>;
			spi_cs_delay = <10	/* hold_high_delay */
				100>; /* clk_cs_delay (unit: us) */
			en_gpio_on_off = <0 /* ldim_dev-gpios index */
				1 /* on_level */
				0>; /* off_level */
			lamp_err_gpio = <0xff>;
				/* ldim_dev-gpios index, 0xff=invalid */
			spi_write_check = <0>; /* 0=disable, 1=enable */

			dim_max_min = <0xfff 0x0>; /* dim_max, dim_min */
			chip_count = <3>;
			ldim_zone_mapping = <0>;
			ldim_bl_profile_mode = <2>; /*0=no profile*/
			ldim_bl_profile_k_bits = <
				3487 24>; /*profile_k, profile_bits*/
			ldim_bl_profile_path =
				"/odm/etc/tvconfig/panel/UHD_2RG_LDIM_BLMCU/bl_profile.bin";

			ldim_cus_param = < /* maximum = 32 x 4 bytes*/
				11
				23
				>;

			cmd_size = <0xff>;
			/* init: (type, data...) */
			/*	 type: 0x00=cmd with delay,
			 *		   0xc0=cmd,
			 *		   0xfd=delay,
			 *		   0xff=ending
			 */
			/*	 data: spi data, fill 0x0 for no use */
			/*	 delay: unit ms */
			init_on = <	0xff 0>;
			init_off = <0xff 0>;
		};
	};

	lcd1:lcd1 {
		compatible = "amlogic, lcd-t7";
		status = "okay";
		index = <1>;
		mode = "tablet";
		fr_auto_policy = <1>; /* 0=disable, 1=60/50hz, 2=60/50/48hz */
		key_valid = <0>;
		clocks = <&clkc CLKID_MIPI_DSI_B
			&clkc CLKID_DSI1_PHY_GATE
			&clkc CLKID_DSI_B_MEAS_GATE>;
		clock-names = "dsi_host_gate",
			"dsi_phy_gate",
			"dsi_meas";
		reg = <0x0 0xfe018000 0x0 0x60	   /* combo dphy */
			0x0 0xfe0b2000 0x0 0x10b0  /* edp_b host */
			0x0 0xfe072000 0x0 0x400   /* mipi_dsi_b host */
			0x0 0xfe016000 0x0 0x200   /* mipi_dsi_b phy */
			0x0 0xfe002000 0x0 0xa0	   /* reset */
			0x0 0xfe004000 0x0 0x70>;  /* periphs */
		interrupts = <0 197 1
			0 194 1
			0 82 1
			0 283 1>;
		interrupt-names = "vsync","vsync2","vsync3","vbyone";
		pinctrl-names = "vbyone","vbyone_off","edp","edp_off";
		pinctrl-0 = <&lcd_vbyone_b_pins>;
		pinctrl-1 = <&lcd_vbyone_b_off_pins>;
		pinctrl-2 = <&lcd_edp_b_pins>;
		pinctrl-3 = <&lcd_edp_b_off_pins>;
		pinctrl_version = <2>; /* for uboot */

		/* power type:(0=cpu_gpio, 2=signal, 3=extern, 0xff=ending) */
		/* power index:(gpios_index, or extern_index, 0xff=invalid) */
		/* power value:(0=output low, 1=output high, 2=input) */
		/* power delay:(unit in ms) */
		lcd_cpu-gpios = <&gpio GPIOY_14 GPIO_ACTIVE_HIGH
			&gpio GPIOY_6 GPIO_ACTIVE_HIGH>;
		lcd_cpu_gpio_names = "GPIOY_14","GPIOY_6";

		lvds_0{
			model_name = "768p-vfreq";
			interface = "lvds"; /*lcd_interface(lvds, vbyone)*/
			basic_setting = <
				1366 768 /*h_active, v_active*/
				1560 806 /*h_period, v_period*/
				8	   /*lcd_bits*/
				16 9>; /*screen_widht, screen_height*/
			range_setting = <
				1460 2000 /*h_period_min, max */
				784 1015  /*v_period_min, max */
				50000000 85000000>; /*pclk_min, max*/
			lcd_timing = <
				56 64 0	  /*hs_width, hs_bp, hs_pol*/
				3  28 0>; /*vs_width, vs_bp, vs_pol*/
			clk_attr = <
				2 /*fr_adj_type
				   *(0=clk, 1=htotal, 2=vtotal, 3=auto_range,
				   * 4=hdmi_mode)
				   */
				15 /*clk_ss_level*/
				1 /*clk_auto_generate*/
				0>; /*pixel_clk(unit in Hz)*/
			lvds_attr = <
				1  /*lvds_repack*/
				0  /*dual_port*/
				0  /*pn_swap*/
				0  /*port_swap*/
				0>; /*lane_reverse*/
			phy_attr=<0x3 0>; /*vswing_level, preem_level*/

			/* power step: type, index, value, delay(ms) */
			power_on_step = <
				0 0 1 50  /*panel power on*/
				2 0 0 0	  /*signal enable*/
				0xff 0 0 0>; /*ending*/
			power_off_step = <
				2 0 0 10  /*signal disable*/
				0 0 0 100 /*panel power off*/
				0xff 0 0 0>; /*ending*/
			backlight_index = <0xff>;
		};
		lvds_3{
			model_name = "AML101WX1-206";
			interface = "lvds"; /*lcd_interface(lvds, vbyone)*/
			basic_setting = <
				1280 800 /*h_active, v_active*/
				1310 813 /*h_period, v_period*/
				8	   /*lcd_bits*/
				217 136>; /*screen_widht, screen_height*/
			range_setting = <
				1280 1280 /*h_period_min, max */
				800 800	 /*v_period_min, max */
				400000000 800000000>; /*pclk_min, max*/
			lcd_timing = <
				2 14 0	 /*hs_width, hs_bp, hs_pol*/
				1 6 0>; /*vs_width, vs_bp, vs_pol*/
			clk_attr = <
				0 /*fr_adj_type
				   *(0=clk, 1=htotal, 2=vtotal, 3=auto_range,
				   * 4=hdmi_mode)
				   */
				15 /*clk_ss_level*/
				1 /*clk_auto_generate*/
				60>; /*pixel_clk(unit in Hz)*/
			lvds_attr = <
				1  /*lvds_repack*/
				0  /*dual_port*/
				0  /*pn_swap*/
				1  /*port_swap*/
				0>; /*lane_reverse*/
			phy_attr=<0x3 0>; /*vswing_level, preem_level*/

			/* power step: type, index, value, delay(ms) */
			power_on_step = <
				0 0 1 50  /*panel power on*/
				2 0 0 0	  /*signal enable*/
				0xff 0 0 0>; /*ending*/
			power_off_step = <
				2 0 0 10  /*signal disable*/
				0 0 0 100  /*panel power off*/
				0xff 0 0 0>; /*ending*/
			backlight_index = <0xff>;
		};
		vbyone_0{
			model_name = "public_2region";
			interface = "vbyone"; /*lcd_interface(lvds, vbyone)*/
			basic_setting = <
				3840 2160 /*h_active, v_active*/
				4400 2250 /*h_period, v_period*/
				10	   /*lcd_bits */
				16 9>; /*screen_widht, screen_height*/
			range_setting = <
				4240 4800 /*h_period_min, max*/
				2200 2760 /*v_period_min, max*/
				480000000 624000000>; /*pclk_min, max*/
			lcd_timing = <
				33 477 0  /*hs_width, hs_bp, hs_pol*/
				6  65 0>; /*vs_width, vs_bp, vs_pol*/
			clk_attr = <
				2 /*fr_adj_type
				   *(0=clk, 1=htotal, 2=vtotal, 3=auto_range,
				   * 4=hdmi_mode)
				   */
				0 /*clk_ss_level*/
				1 /*clk_auto_generate*/
				0>; /*pixel_clk(unit in Hz)*/
			vbyone_attr = <
				8 /*lane_count*/
				2 /*region_num*/
				4 /*byte_mode*/
				4>; /*color_fmt*/
			vbyone_intr_enable = <
				1 /*vbyone_intr_enable */
				3>; /*vbyone_vsync_intr_enable*/
			phy_attr=<0x7 1>; /* vswing_level, preem_level */
			hw_filter=<0 0>;  /* filter_time, filter_cnt*/

			/* power step: type, index, value, delay(ms) */
			power_on_step = <
				0 0 1 200  /*panel power on*/
				2 0 0 10  /*signal enable*/
				0xff 0 0 0>; /*ending*/
			power_off_step = <
				2 0 0 10 /*signal disable*/
				0 0 0 500  /*panel power off*/
				0xff 0 0 0>; /*ending*/
			backlight_index = <0>;
		};
		vbyone_1{
			model_name = "public_1region";
			interface = "vbyone"; /*lcd_interface(lvds, vbyone)*/
			basic_setting = <
				3840 2160 /*h_active, v_active*/
				4400 2250 /*h_period, v_period*/
				10	   /*lcd_bits*/
				16 9>; /*screen_widht, screen_height*/
			range_setting = <
				4240 4800 /*h_period_min, max*/
				2200 2790 /*v_period_min, max*/
				552000000 632000000>; /*pclk_min,max*/
			lcd_timing = <
				33 477 0   /*hs_width, hs_bp, hs_pol*/
				6  65  0>; /*vs_width, vs_bp, vs_pol*/
			clk_attr = <
				2 /*fr_adj_type
				   *(0=clk, 1=htotal, 2=vtotal, 3=auto_range,
				   * 4=hdmi_mode)
				   */
				0 /*clk_ss_level*/
				1 /*clk_auto_generate*/
				0>; /*pixel_clk(unit in Hz)*/
			vbyone_attr = <
				8 /*lane_count*/
				1 /*region_num*/
				4 /*byte_mode*/
				4>; /*color_fmt*/
			vbyone_intr_enable = <
				1	/*vbyone_intr_enable*/
				3>; /*vbyone_vsync_intr_enable*/
			phy_attr=<0x7 1>; /* vswing_level, preem_level */
			hw_filter=<0 0>;  /* filter_time, filter_cnt*/

			/* power step: type, index, value, delay(ms) */
			power_on_step = <
				0 0 1 200  /*panel power on*/
				2 0 0 10 /*signal enable*/
				0xff 0 0 0>; /*ending*/
			power_off_step = <
				2 0 0 10  /*signal disable*/
				0 0 0 500  /*panel power off*/
				0xff 0 0 0>; /*ending*/
			backlight_index = <0>;
		};
		vbyone_2{
			model_name = "vbyone_1region_hdmi";
			interface = "vbyone"; /*lcd_interface(lvds, vbyone)*/
			basic_setting = <
				3840 2160 /*h_active, v_active*/
				4400 2250 /*h_period, v_period*/
				10	   /*lcd_bits */
				16 9>; /*screen_widht, screen_height*/
			range_setting = <
				4240 4800 /*h_period_min, max*/
				2200 2760 /*v_period_min, max*/
				480000000 624000000>; /*pclk_min, max*/
			lcd_timing = <
				33 477 0  /*hs_width, hs_bp, hs_pol*/
				6  65 0>; /*vs_width, vs_bp, vs_pol*/
			clk_attr = <
				4 /*fr_adj_type
				   *(0=clk, 1=htotal, 2=vtotal, 3=auto_range,
				   * 4=hdmi_mode)
				   */
				0 /*clk_ss_level*/
				1 /*clk_auto_generate*/
				0>; /*pixel_clk(unit in Hz)*/
			vbyone_attr = <
				8 /*lane_count*/
				1 /*region_num*/
				4 /*byte_mode*/
				4>; /*color_fmt*/
			vbyone_intr_enable = <
				1 /*vbyone_intr_enable */
				3>; /*vbyone_vsync_intr_enable*/
			phy_attr=<0x7 1>; /* vswing_level, preem_level */
			hw_filter=<0 0>;  /* filter_time, filter_cnt*/

			/* power step: type, index, value, delay(ms) */
			power_on_step = <
				0 0 1 20  /*panel power on*/
				2 0 0 0	 /*signal enable*/
				0xff 0 0 0>; /*ending*/
			power_off_step = <
				2 0 0 20 /*signal disable*/
				0 0 0 100 /*panel power off*/
				0xff 0 0 0>; /*ending*/
			backlight_index = <0xff>;
		};
		vbyone_3{
			model_name = "vbyone_2region_hdmi";
			interface = "vbyone"; /*lcd_interface(lvds, vbyone)*/
			basic_setting = <
				3840 2160 /*h_active, v_active*/
				4400 2250 /*h_period, v_period*/
				10	   /*lcd_bits */
				16 9>; /*screen_widht, screen_height*/
			range_setting = <
				4240 4800 /*h_period_min, max*/
				2200 2760 /*v_period_min, max*/
				480000000 624000000>; /*pclk_min, max*/
			lcd_timing = <
				33 477 0  /*hs_width, hs_bp, hs_pol*/
				6  65 0>; /*vs_width, vs_bp, vs_pol*/
			clk_attr = <
				4 /*fr_adj_type
				   *(0=clk, 1=htotal, 2=vtotal, 3=auto_range,
				   * 4=hdmi_mode)
				   */
				0 /*clk_ss_level*/
				1 /*clk_auto_generate*/
				0>; /*pixel_clk(unit in Hz)*/
			vbyone_attr = <
				8 /*lane_count*/
				2 /*region_num*/
				4 /*byte_mode*/
				4>; /*color_fmt*/
			vbyone_intr_enable = <
				1 /*vbyone_intr_enable */
				3>; /*vbyone_vsync_intr_enable*/
			phy_attr=<0x7 1>; /* vswing_level, preem_level */
			hw_filter=<0 0>;  /* filter_time, filter_cnt*/

			/* power step: type, index, value, delay(ms) */
			power_on_step = <
				0 0 1 20  /*panel power on*/
				2 0 0 0	 /*signal enable*/
				0xff 0 0 0>; /*ending*/
			power_off_step = <
				2 0 0 20 /*signal disable*/
				0 0 0 100 /*panel power off*/
				0xff 0 0 0>; /*ending*/
			backlight_index = <0xff>;
		};

		edp_0{
			model_name = "edp_1080p";
			interface = "edp"; /*lcd_interface(lvds, vbyone)*/
			basic_setting = <
				1920 1080 /*h_active, v_active*/
				2200 1125 /*h_period, v_period*/
				8	   /*lcd_bits*/
				16 9>; /*screen_widht, screen_height*/
			range_setting = <
				2080 2720 /*h_period min, max*/
				1100 1380 /*v_period min, max*/
				133940000 156000000>; /*pclk_min, max*/
			lcd_timing = <
				44 148 0   /*hs_width, hs_bp, hs_pol*/
				5  30  0>; /*vs_width, vs_bp, vs_pol*/
			clk_attr = <
				0 /*fr_adj_type
				   *(0=clk, 1=htotal, 2=vtotal, 3=auto_range,
				   * 4=hdmi_mode)
				   */
				0 /*clk_ss_level */
				1 /*clk_auto_generate*/
				0>; /*pixel_clk(unit in Hz)*/
			edp_attr = <
				2 /*max_lane_count: 1,2,4*/
				1 /*max_link_rate: 0=1.62G, 1=2.7G*/
				0 /*training_mode*/
				0 /*reserved*/
				0 /*reserved */
				0 /*reserved */
				0 /*reserved */
				0 /*reserved */
				0>; /*reserved*/
			phy_attr=<0x5 1>; /*vswing_level, preem_level*/

			/* power step: type, index, value, delay(ms) */
			power_on_step = <
				0 0 1 50  /*panel power on*/
				2 0 0 0	  /*signal enable*/
				0xff 0 0 0>; /*ending*/
			power_off_step = <
				2 0 0 10  /*signal disable*/
				0 0 0 200  /*panel power on*/
				0xff 0 0 0>; /*ending*/
			backlight_index = <0x0>;
		};
		mipi_0{
			model_name = "TL070WSH27";
			interface = "mipi";
			basic_setting = <1024 600 /*h_active, v_active*/
				1250 630 /*h_period, v_period*/
				8 /*lcd_bits*/
				154 86>; /*screen_widht, screen_height*/
			lcd_timing = <80 100 0 /*hs_width, hs_bp, hs_pol*/
				5 20 0>; /*vs_width, vs_bp, vs_pol*/
			clk_attr = <0 /*fr_adj_type(0=clk, 1=htotal, 2=vtotal)*/
				0 /*clk_ss_level */
				1 /*clk_auto_generate*/
				47250000>; /*pixel_clk(unit in Hz)*/
			mipi_attr = <4 /*lane_num*/
				300 /*bit_rate_max(MHz)*/
				0 /*factor(*100, default 0 for auto)*/
				1 /*operation_mode_init(0=video, 1=command)*/
				0 /*operation_mode_display(0=video, 1=command)*/
				2 /*
				   *video_mode_type
				   *(0=sync_pulse,1=sync_event,2=burst)
				   */
				1 /*clk_always_hs(0=disable,1=enable)*/
				0>; /*phy_switch(0=auto,1=standard,2=slow)*/

			/* dsi_init: data_type, num, data... */
			dsi_init_on = <0x05 1 0x11
					0xfd 1 20	  /*delay(ms)*/
					0x05 1 0x29
					0xfd 1 20	  /*delay(ms)*/
					0xff 0>; /*ending*/
			dsi_init_off = <0x05 1 0x28
					0xfd 1 10	  /*delay(ms)*/
					0x05 1 0x10
					0xfd 1 10	  /*delay(ms)*/
					0xff 0>; /*ending*/
			extern_init = <0xff>; /*0xff for invalid*/

			/* power step: type, index, value, delay(ms) */
			power_on_step = <
				0 0 1 100
				0 1 0 10
				0 1 1 20
				2 0 0 0
				0xff 0 0 0>; /*ending*/
			power_off_step = <
				2 0 0 50
				0 1 0 10
				0 0 0 100
				0xff 0 0 0>; /*ending*/
			backlight_index = <0x1>;
		};
		mipi_1{
			model_name = "SLT_720P";
			interface = "mipi";
			basic_setting = <1280 720 /*h_active, v_active*/
				1590 750 /*h_period, v_period*/
				8 /*lcd_bits*/
				16 9>; /*screen_widht, screen_height*/
			lcd_timing = <40 60 0 /*hs_width,hs_bp,hs_pol*/
				5 20 0>; /*vs_width,vs_bp,vs_pol*/
			clk_attr = <0 /*fr_adj_type(0=clock,1=htotal,2=vtotal)*/
				0 /*clk_ss_level*/
				1 /*clk_auto_generate*/
				74250000>; /*pixel_clk(unit in Hz)*/
			mipi_attr = <4 /*lane_num*/
				550 /*bit_rate_max(MHz)*/
				0 /*factor(*100, default 0 for auto)*/
				1 /*operation_mode_init(0=video, 1=command)*/
				0 /*operation_mode_display(0=video, 1=command)*/
				0 /*
				   *video_mode_type
				   *(0=sync_pulse,1=sync_event,2=burst)
				   */
				1 /*clk_always_hs(0=disable,1=enable)*/
				0>; /*phy_switch(0=auto,1=standard,2=slow)*/
				/* dsi_init: data_type, num, data... */
			dsi_init_on = <
				0x05 1 0x11
				0xff 200
				0x05 1 0x29
				0xff 20
				0xff 0xff>; /* ending flag */
			dsi_init_off = <
				0x05 1 0x28
				0xff 10
				0x05 1 0x10
				0xff 10
				0xff 0xff>; /* ending flag */
				/* extern_init: 0xff for invalid */
			extern_init = <0xff>;
				/* power step: type,index,value,delay(ms) */
			power_on_step = <
					3 7 0 100
					2 0 0 0
					0xff 0 0 0>;
			power_off_step = <
					2 0 0 0
					0xff 0 0 0>;
			backlight_index = <0xff>;
		};
		ports {
			port {
				#address-cells = <1>;
				#size-cells = <0>;
				lcd1_to_drm: endpoint@0 {
					reg = <0>;
					remote-endpoint = <0>;
				};
			};
		};
	};

	backlight1{
		compatible = "amlogic, backlight-t7";
		status = "okay";
		index = <1>;
		key_valid = <0>;
		pinctrl-names = "pwm_on",
				"pwm_off";
		pinctrl-0 = <&pwm_f_pins>; /* GPIOY_8*/
		pinctrl-1 = <&bl1_pwm_off_pins>; /* GPIOY_8*/
		pinctrl_version = <2>; /* for uboot */
		interrupts = <0 197 1
			0 194 1
			0 82 1>;
		interrupt-names = "vsync","vsync2","vsync3";
		bl_pwm_config = <&bl_pwm_conf>;

		/* pwm port: PWM_A, PWM_B, PWM_C, PWM_D, PWM_E, PWM_F, PWM_VS*/
		/* power index:(point gpios_index, 0xff=invalid) */
		/* power value:(0=output low, 1=output high, 2=input) */
		/* power delay:(unit in ms) */
		bl-gpios = <&gpio GPIOY_9 GPIO_ACTIVE_HIGH
			&gpio GPIOY_8 GPIO_ACTIVE_HIGH>;
		bl_gpio_names = "GPIOY_9","GPIOY_8";

		backlight_0{
			index = <0>;
			bl_name = "backlight_pwm";
			bl_level_default_uboot_kernel = <255 255>;
			bl_level_attr = <255 10 /*max, min*/
				128 128>; /*mid, mid_mapping*/
			bl_ctrl_method = <1>; /*1=pwm,2=pwm_combo*/
			bl_power_attr = <0 /*en_gpio_index*/
				1 0 /*on_value, off_value*/
				200 200>; /*on_delay(ms), off_delay(ms)*/
			bl_pwm_port = "PWM_F";
			bl_pwm_attr = <1 /*pwm_method(0=negative, 1=positvie)*/
				180 /*pwm_freq(pwm:Hz, pwm_vs:multiple of vs)*/
				100 25>; /*duty_max(%), duty_min(%)*/
			bl_pwm_power = <1 0 /*pwm_gpio_index, pwm_gpio_off*/
				10 10>; /*pwm_on_delay(ms), pwm_off_delay(ms)*/
			en_sequence_reverse = <0>; /* 1 for reverse */
		};

		backlight_1{
			index = <1>;
			bl_name = "backlight_pwm";
			bl_level_default_uboot_kernel = <255 255>;
			bl_level_attr = <255 10 /*max, min*/
				128 128>; /*mid, mid_mapping*/
			bl_ctrl_method = <1>; /*1=pwm,2=pwm_combo*/
			bl_power_attr = <0 /*en_gpio_index*/
				1 0 /*on_value, off_value*/
				200 200>; /*on_delay(ms), off_delay(ms)*/
			bl_pwm_port = "PWM_F";
			bl_pwm_attr = <0 /*pwm_method(0=negative, 1=positvie)*/
				180 /*pwm_freq(pwm:Hz, pwm_vs:multiple of vs)*/
				100 25>; /*duty_max(%), duty_min(%)*/
			bl_pwm_power = <1 0 /*pwm_gpio_index, pwm_gpio_off*/
				10 10>; /*pwm_on_delay(ms), pwm_off_delay(ms)*/
			en_sequence_reverse = <0>; /* 1 for reverse */
		};
	};

	lcd2:lcd2 {
		compatible = "amlogic, lcd-t7";
		status = "okay";
		index = <2>;
		mode = "tablet";
		fr_auto_policy = <0>; /* 0=disable, 1=60/50hz, 2=60/50/48hz */
		key_valid = <0>;
		reg = <0x0 0xfe018000 0x0 0x60	   /* combo dphy */
			0x0 0xfe0b0000 0x0 0x10b0  /* edp_a host */
			0x0 0xfe074000 0x0 0x400   /* mipi_dsi_a host */
			0x0 0xfe014000 0x0 0x200   /* mipi_dsi_a phy */
			0x0 0xfe002000 0x0 0xa0	   /* reset */
			0x0 0xfe004000 0x0 0x70>;  /* periphs */
		interrupts = <0 197 1
			0 194 1
			0 82 1>;
		interrupt-names = "vsync","vsync2","vsync3";
		pinctrl_version = <2>; /* for uboot */

		/* power type:(0=cpu_gpio, 2=signal, 3=extern, 0xff=ending) */
		/* power index:(gpios_index, or extern_index, 0xff=invalid) */
		/* power value:(0=output low, 1=output high, 2=input) */
		/* power delay:(unit in ms) */
		lcd_cpu-gpios = <&gpio GPIOY_14 GPIO_ACTIVE_HIGH>;
		lcd_cpu_gpio_names = "GPIOY_14";

		lvds_0{
			model_name = "1080p-vfreq";
			interface = "lvds"; /*lcd_interface(lvds, vbyone)*/
			basic_setting = <
				1920 1080 /*h_active, v_active*/
				2200 1125 /*h_period, v_period*/
				8	   /*lcd_bits */
				16 9>; /*screen_widht, screen_height*/
			range_setting = <
				2060 2650  /*h_period_min,max*/
				1100 1480  /*v_period_min,max*/
				120000000 160000000>; /*pclk_min,max*/
			lcd_timing = <
				44 148 0  /*hs_width, hs_bp, hs_pol*/
				5  30 0>; /*vs_width, vs_bp, vs_pol*/
			clk_attr = <
				2 /*fr_adj_type
				   *(0=clk, 1=htotal, 2=vtotal, 3=auto_range,
				   * 4=hdmi_mode)
				   */
				0 /*clk_ss_level*/
				1 /*clk_auto_generate*/
				0>; /*pixel_clk(unit in Hz)*/
			lvds_attr = <
				1  /*lvds_repack*/
				1  /*dual_port*/
				0  /*pn_swap*/
				0  /*port_swap*/
				0>; /*lane_reverse*/
			phy_attr=<0x3 0>; /*vswing_level, preem_level*/

			/* power step: type, index, value, delay(ms) */
			power_on_step = <
				0 0 1 50  /*panel power on*/
				2 0 0 0	  /*signal enable*/
				0xff 0 0 0>; /*ending*/
			power_off_step = <
				2 0 0 10  /*signal disable*/
				0 0 0 100  /*panel power off*/
				0xff 0 0 0>; /*ending*/
			backlight_index = <0xff>;
		};
		lvds_1{
			model_name = "1080p-hfreq_hdmi";
			interface = "lvds"; /*lcd_interface(lvds, vbyone)*/
			basic_setting = <
				1920 1080 /*h_active, v_active*/
				2200 1125 /*h_period, v_period*/
				8	   /*lcd_bits*/
				16 9>; /*screen_widht, screen_height*/
			range_setting = <
				2080 2720 /*h_period min, max*/
				1100 1380 /*v_period min, max*/
				133940000 156000000>; /*pclk_min, max*/
			lcd_timing = <
				44 148 0   /*hs_width, hs_bp, hs_pol*/
				5  30  0>; /*vs_width, vs_bp, vs_pol*/
			clk_attr = <
				4 /*fr_adj_type
				   *(0=clk, 1=htotal, 2=vtotal, 3=auto_range,
				   * 4=hdmi_mode)
				   */
				0 /*clk_ss_level */
				1 /*clk_auto_generate*/
				0>; /*pixel_clk(unit in Hz)*/
			lvds_attr = <
				1 /*lvds_repack*/
				1 /*dual_port*/
				0 /*pn_swap*/
				0 /*port_swap*/
				0>; /*lane_reverse*/
			phy_attr=<0x3 0>; /*vswing_level, preem_level*/

			/* power step: type, index, value, delay(ms) */
			power_on_step = <
				0 0 1 50  /*panel power on*/
				2 0 0 0	  /*signal enable*/
				0xff 0 0 0>; /*ending*/
			power_off_step = <
				2 0 0 10  /*signal disable*/
				0 0 0 100  /*panel power off*/
				0xff 0 0 0>; /*ending*/
			backlight_index = <0xff>;
		};
		lvds_3{
			model_name = "AML101WX1-206";
			interface = "lvds"; /*lcd_interface(lvds, vbyone)*/
			basic_setting = <
				1280 800 /*h_active, v_active*/
				1310 813 /*h_period, v_period*/
				8	   /*lcd_bits*/
				217 136>; /*screen_widht, screen_height*/
			range_setting = <
				1280 1280 /*h_period_min, max */
				800 800	 /*v_period_min, max */
				400000000 800000000>; /*pclk_min, max*/
			lcd_timing = <
				2 14 0	 /*hs_width, hs_bp, hs_pol*/
				1 6 0>; /*vs_width, vs_bp, vs_pol*/
			clk_attr = <
				0 /*fr_adj_type
				   *(0=clk, 1=htotal, 2=vtotal, 3=auto_range,
				   * 4=hdmi_mode)
				   */
				15 /*clk_ss_level*/
				1 /*clk_auto_generate*/
				60>; /*pixel_clk(unit in Hz)*/
			lvds_attr = <
				1  /*lvds_repack*/
				0  /*dual_port*/
				0  /*pn_swap*/
				1  /*port_swap*/
				0>; /*lane_reverse*/
			phy_attr=<0x3 0>; /*vswing_level, preem_level*/

			/* power step: type, index, value, delay(ms) */
			power_on_step = <
				0 0 1 50  /*panel power on*/
				2 0 0 0	  /*signal enable*/
				0xff 0 0 0>; /*ending*/
			power_off_step = <
				2 0 0 10  /*signal disable*/
				0 0 0 100  /*panel power off*/
				0xff 0 0 0>; /*ending*/
			backlight_index = <0xff>;
		};
	};

	bl_pwm_conf:bl_pwm_conf{
		pwm_channel_0 {
			pwm_port = "PWM_E";
			pwms = <&pwm_ef MESON_PWM_0 30040 0>;
		};
		pwm_channel_1 {
			pwm_port = "PWM_F";
			pwms = <&pwm_ef MESON_PWM_1 30040 0>;
		};
	};

}; /* end of / */
